# f28003x_access_protection_regs register map
Vendor: Texas Instruments
Peripheral module from a debugger description file (folder C2000).
Address unit: 16 bits
Registers are 32-bit, read-only, no defined reset value unless marked. A register's access mark holds for its fields unless they carry their own. Offsets are as the file gives them; lines under a group give offsets from that group; [hi:lo] are bit positions; {n}, {i} and the like mark numbered series; 'fields as' and 'values as' point back to an identical list; <NAME> marks a mode.

## ACCESS_PROTECTION_REGS — ACCESS PROTECTION Registers
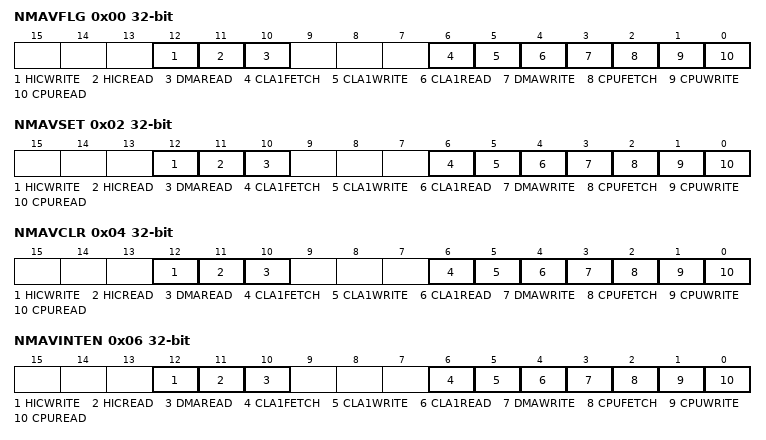
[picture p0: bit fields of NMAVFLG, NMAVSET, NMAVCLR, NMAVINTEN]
0x00 NMAVFLG — Non-Master Access Violation Flag Register
  [12] HICWRITE — Non Master HIC Write Access Violation Flag
  [11] HICREAD — Non Master HIC Read Access Violation Flag
  [10] DMAREAD — Non Master DMA Read Access Violation Flag
  [6] CLA1FETCH — Non Master CLA1 Fetch Access Violation Flag
  [5] CLA1WRITE — Non Master CLA1 Write Access Violation Flag
  [4] CLA1READ — Non Master CLA1 Read Access Violation Flag
  [3] DMAWRITE — Non Master DMA Write Access Violation Flag
  [2] CPUFETCH — Non Master CPU Fetch Access Violation Flag
  [1] CPUWRITE — Non Master CPU Write Access Violation Flag
  [0] CPUREAD — Non Master CPU Read Access Violation Flag
0x02 NMAVSET rw — Non-Master Access Violation Flag Set Register
  [12] HICWRITE — Non Master HIC Write Access Violation Flag Set
  [11] HICREAD — Non Master HIC Read Access Violation Flag Set
  [10] DMAREAD — Non Master DMA Read Access Violation Flag Set
  [6] CLA1FETCH — Non Master CLA1 Fetch Access Violation Flag Set
  [5] CLA1WRITE — Non Master CLA1 Write Access Violation Flag Set
  [4] CLA1READ — Non Master CLA1 Read Access Violation Flag Set
  [3] DMAWRITE — Non Master DMA Write Access Violation Flag Set
  [2] CPUFETCH — Non Master CPU Fetch Access Violation Flag Set
  [1] CPUWRITE — Non Master CPU Write Access Violation Flag Set
  [0] CPUREAD — Non Master CPU Read Access Violation Flag Set
0x04 NMAVCLR rw — Non-Master Access Violation Flag Clear Register
  [12] HICWRITE — Non Master HIC Write Access Violation Flag Clear
  [11] HICREAD — Non Master HIC Read Access Violation Flag Clear
  [10] DMAREAD — Non Master DMA Read Access Violation Flag Clear
  [6] CLA1FETCH — Non Master CLA1 Fetch Access Violation Flag Clear
  [5] CLA1WRITE — Non Master CLA1 Write Access Violation Flag Clear
  [4] CLA1READ — Non Master CLA1 Read Access Violation Flag Clear
  [3] DMAWRITE — Non Master DMA Write Access Violation Flag Clear
  [2] CPUFETCH — Non Master CPU Fetch Access Violation Flag Clear
  [1] CPUWRITE — Non Master CPU Write Access Violation Flag Clear
  [0] CPUREAD — Non Master CPU Read Access Violation Flag Clear
0x06 NMAVINTEN rw — Non-Master Access Violation Interrupt Enable Register
  [12] HICWRITE — Non Master HIC Write Access Violation Interrupt Enable
  [11] HICREAD — Non Master HIC Read Access Violation Interrupt Enable
  [10] DMAREAD — Non Master DMA Read Access Violation Interrupt Enable
  [6] CLA1FETCH — Non Master CLA1 Fetch Access Violation Interrupt Enable
  [5] CLA1WRITE — Non Master CLA1 Write Access Violation Interrupt Enable
  [4] CLA1READ — Non Master CLA1 Read Access Violation Interrupt Enable
  [3] DMAWRITE — Non Master DMA Write Access Violation Interrupt Enable
  [2] CPUFETCH — Non Master CPU Fetch Access Violation Interrupt Enable
  [1] CPUWRITE — Non Master CPU Write Access Violation Interrupt Enable
  [0] CPUREAD — Non Master CPU Read Access Violation Interrupt Enable
0x08 NMCPURDAVADDR — Non-Master CPU Read Access Violation Address
  [31:0] NMCPURDAVADDR — Non Master CPU read access violation address register.
0x0A NMCPUWRAVADDR — Non-Master CPU Write Access Violation Address
  [31:0] NMCPUWRAVADDR — Non Master CPU write access violation address register.
0x0C NMCPUFAVADDR — Non-Master CPU Fetch Access Violation Address
  [31:0] NMCPUFAVADDR — Non Master CPU fetch access violation address register.
0x0E NMDMAWRAVADDR — Non-Master DMA Write Access Violation Address
  [31:0] NMDMAWRAVADDR — Non Master DMA write access violation address register.
0x10 NMCLA1RDAVADDR — Non-Master CLA1 Read Access Violation Address
  [31:0] NMCLA1RDAVADDR — Non Master CLA1 read access violation address register.
0x12 NMCLA1WRAVADDR — Non-Master CLA1 Write Access Violation Address
  [31:0] NMCLA1WRAVADDR — Non Master CLA1 write access violation address register.
0x14 NMCLA1FAVADDR — Non-Master CLA1 Fetch Access Violation Address
  [31:0] NMCLA1FAVADDR — Non Master CLA1 fetch access violation address register.
0x1C NMDMARDAVADDR — Non-Master DMA Read Access Violation Address
  [31:0] NMDMARDAVADDR — Non Master DMA read access violation address register.
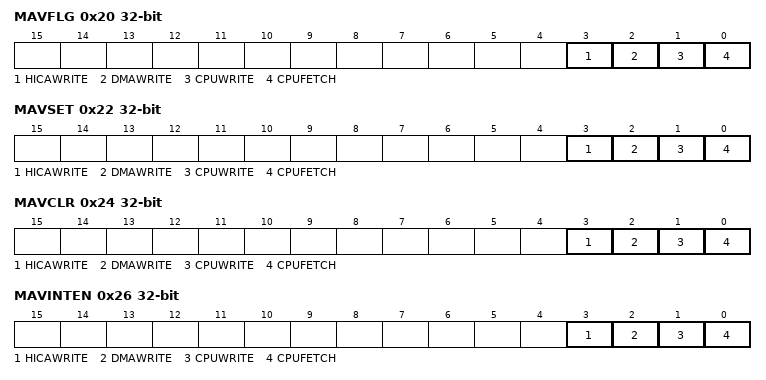
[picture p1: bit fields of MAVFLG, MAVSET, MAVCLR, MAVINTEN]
0x20 MAVFLG — Master Access Violation Flag Register
  [3] HICAWRITE — Master HICA Write Access Violation Flag
  [2] DMAWRITE — Master DMA Write Access Violation Flag
  [1] CPUWRITE — Master CPU Write Access Violation Flag
  [0] CPUFETCH — Master CPU Fetch Access Violation Flag
0x22 MAVSET rw — Master Access Violation Flag Set Register
  [3] HICAWRITE — Master HICA Write Access Violation Flag Set
  [2] DMAWRITE — Master DMA Write Access Violation Flag Set
  [1] CPUWRITE — Master CPU Write Access Violation Flag Set
  [0] CPUFETCH — Master CPU Fetch Access Violation Flag Set
0x24 MAVCLR rw — Master Access Violation Flag Clear Register
  [3] HICAWRITE — Master HICA Write Access Violation Flag Clear
  [2] DMAWRITE — Master DMA Write Access Violation Flag Clear
  [1] CPUWRITE — Master CPU Write Access Violation Flag Clear
  [0] CPUFETCH — Master CPU Fetch Access Violation Flag Clear
0x26 MAVINTEN rw — Master Access Violation Interrupt Enable Register
  [3] HICAWRITE — Master HICA Write Access Violation Interrupt Enable
  [2] DMAWRITE — Master DMA Write Access Violation Interrupt Enable
  [1] CPUWRITE — Master CPU Write Access Violation Interrupt Enable
  [0] CPUFETCH — Master CPU Fetch Access Violation Interrupt Enable
0x28 MCPUFAVADDR — Master CPU Fetch Access Violation Address
  [31:0] MCPUFAVADDR — Master CPU fetch access violation address register.
0x2A MCPUWRAVADDR — Master CPU Write Access Violation Address
  [31:0] MCPUWRAVADDR — Master CPU write access violation address register.
0x2C MDMAWRAVADDR — Master DMA Write Access Violation Address
  [31:0] MDMAWRAVADDR — Master DMA write access violation address register.
0x2E MHICWRAVADDR — Master HIC Write Access Violation Address
  [31:0] MHICWRAVADDR — Master HICA write access violation address register.
0x3C NMHICRDAVADDR — Non-Master HIC Read Access Violation Address
  [31:0] NMHICRDAVADDR — Non Master HIC read access violation address register.
0x3E NMHICWRAVADDR — Non-Master HIC Write Access Violation Address
  [31:0] NMHICWRAVADDR — Non Master HIC write access violation address register.
